# NUC029AN_v1 register map
File version: 1.0
Registers are 32-bit, read-write, reset 0x0 unless marked. A register's access mark holds for its fields unless they carry their own. Offsets are from the block's base; [hi:lo] are bit positions; {n}, {i} and the like mark numbered series; 'fields as' and 'values as' point back to an identical list.

## ADC — ADC Register Map
Base 0x400E0000
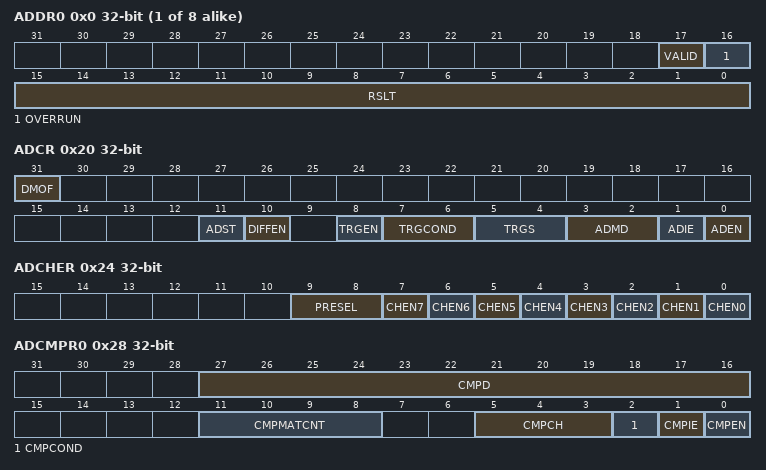
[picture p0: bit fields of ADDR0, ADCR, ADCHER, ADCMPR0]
{0x0+4i} ADDR{i} ro (i=0..7) — ADC Data Register {i}
  [17] VALID — Valid Flag. This bit is set to 1 when corresponding channel analog input conversion is completed and cleared by hardware after ADDR register is read. This is a read only bit
    0=Data in RSLT bits is not valid; 1=Data in RSLT bits is valid
  [16] OVERRUN — Over Run Flag (Read Only). If converted data in RSLT has not been read before new conversion result is loaded to this register, OVERRUN is set to 1. It is cleared by hardware after ADDR register is read.
    0=Data in RSLT is recent conversion result; 1=Data in RSLT is overwrite
  [15:0] RSLT — A/D Conversion Result. This field contains conversion result of ADC.
0x20 ADCR — ADC Control Register
  [31] DMOF — A/D differential input Mode Output Format
    0=A/D Conversion result will be filled in RSLT at ADDRx registers with unsigned format; 1=A/D Conversion result will be filled in RSLT at ADDRx registers with 2'complement format
  [11] ADST — A/D Conversion Start. ADST bit can be set to 1 from two sources: software and external pin STADC. ADST will be cleared to 0 by hardware automatically at the ends of single mode and single-cycle scan mode. In continuous scan and burst modes, A/D conversion is continuously performed until software write 0 to this bit or chip reset.
    0=Conversion stopped and A/D converter enter idle state; 1=Conversion start
  [10] DIFFEN — Differential Input Mode Enable
    0=single-end analog input mode; 1=differential analog input mode
  [8] TRGEN — External Trigger Enable. Enable or disable triggering of A/D conversion by external STADC pin or PWM trigger. ADC external trigger function is only supported in single-cycle scan mode.
    0=Disable; 1=Enable
  [7:6] TRGCOND — External Trigger Condition. These two bits decide external pin STADC trigger event is level or edge. The signal must be kept at stable state at least 8 PCLKs for level trigger and 4 PCLKs at high and low state for edge trigger.
    0=Low level; 1=High level; 2=Falling edge; 3=Rising edge
  [5:4] TRGS — Hardware Trigger Source. Software should disable TRGEN and ADST before change TRGS. In hardware trigger mode, the ADST bit is set by the external trigger from STADC.
    0=A/D conversion is started by external STADC pin; 3=A/D conversion is started by PWM trigger
  [3:2] ADMD — A/D Converter Operation Mode. When changing the operation mode, software should disable ADST bit firstly. Note: In Burst Mode, the A/D result data always at Data Register 0.
    0=Single conversion; 1=Burst conversion; 2=Single-cycle scan; 3=Continuous scan
  [1] ADIE — A/D Interrupt Enable. A/D conversion end interrupt request is generated if ADIE bit is set to 1.
    0=Disable A/D interrupt function; 1=Enable A/D interrupt function
  [0] ADEN — A/D Converter Enable. Before starting A/D conversion function, this bit should be set to 1. Clear it to 0 to disable A/D converter analog circuit power consumption.
    0=Disable; 1=Enable
0x24 ADCHER — ADC Channel Enable Register
  [9:8] PRESEL — Analog Input Channel 7 select. Note: When software select the band-gap voltage as the analog input source of ADC channel 7, ADC clock rate needs to be limited to lower than 300 KHz.
    0=External Analog Input; 1=Internal Bandgap voltage; 2=Internal temperature sensor
  [n] CHEN{n} (n=0..7) — Analog Input Channel {n} Enable
    0=Disable; 1=Enable
0x28 ADCMPR0 — ADC Compare Register 0
  [27:16] CMPD — Comparison Data. The 12 bits data is used to compare with conversion result of specified channel. When DMOF bit is set to 0, ADC comparator compares CMPD with conversion result with unsigned format. CMPD should be filled in unsigned format. When DMOF bit is set to 1, ADC comparator compares CMPD with conversion result with 2'complement format. CMPD should be filled in 2'complement format.
  [11:8] CMPMATCNT — Compare Match Count. When the specified A/D channel analog conversion result matches the compare condition defined by CMPCOND[2], the internal match counter will increase 1. When the internal counter reaches the value to (CMPMATCNT +1), the CMPFx bit will be set.
  [5:3] CMPCH — Compare Channel Selection
    {v}=Channel {v} conversion result is selected to be compared (v=0..7)
  [2] CMPCOND — Compare Condition. Note: When the internal counter reaches the value to (CMPMATCNT +1), the CMPFx bit will be set.
    0=Set the compare condition as that when a 12-bit A/D conversion result is less than the 12-bit CMPD (ADCMPRx[27:16]), the internal match counter will increase one; 1=Set the compare condition as that when a 12-bit A/D conversion result is greater or equal to the 12-bit CMPD (ADCMPRx[27:16]), the internal match counter will increase one
  [1] CMPIE — Compare Interrupt Enable. If the compare function is enabled and the compare condition matches the setting of CMPCOND and CMPMATCNT, CMPFx bit will be asserted, in the meanwhile, if CMPIE is set to 1, a compare interrupt request is generated.
    0=Disable compare function interrupt; 1=Enable compare function interrupt
  [0] CMPEN — Compare Enable. Set this bit to 1 to enable ADC controller to compare CMPD[11:0] with specified channel conversion result when converted data is loaded into ADDR register.
    0=Disable compare function; 1=Enable compare function
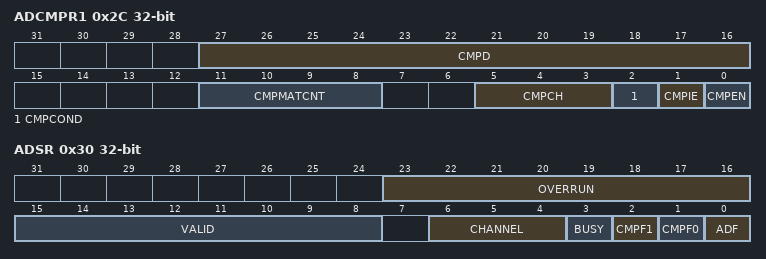
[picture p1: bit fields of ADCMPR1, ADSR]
0x2C ADCMPR1 — ADC Compare Register 1
  fields as ADCMPR0
0x30 ADSR — ADC Status Register
  [23:16] OVERRUN ro — Over Run flag (Read Only). It is a mirror to OVERRUN bit in ADDRx. When ADC in Burst Mode, and the FIFO is overrun, OVERRUN[7:0] will all set to 1.
  [15:8] VALID ro — Data Valid flag (Read Only). It is a mirror of VALID bit in ADDRx. When ADC in Burst Mode, and the FIFO is valid, VALID[7:0] will all set to 1.
  [6:4] CHANNEL — Current Conversion Channel. It is read only.
  [3] BUSY — BUSY/IDLE. This bit is mirror of as ADST bit in ADCR. It is read only.
    0=A/D converter is in idle state; 1=A/D converter is busy at conversion
  [2] CMPF1 — Compare Flag. When the selected channel A/D conversion result meets setting condition in ADCMPR1 then this bit is set to 1. And it is cleared by writing 1 to self.
    0=Conversion result in ADDR does not meet ADCMPR1 setting; 1=Conversion result in ADDR meets ADCMPR1 setting
  [1] CMPF0 — Compare Flag. When the selected channel A/D conversion result meets setting condition in ADCMPR0 then this bit is set to 1. And it is cleared by writing 1 to self.
    0=Conversion result in ADDR does not meet ADCMPR0 setting; 1=Conversion result in ADDR meets ADCMPR0setting
  [0] ADF — A/D Conversion End Flag. A status flag that indicates the end of A/D conversion. ADF is set to 1 at these three conditions: When A/D conversion ends in single mode. When A/D conversion ends on all specified channels in scan mode. When more than 4 samples in FIFO in Burst mode. This flag can be cleared by writing 1 to self.
0x44 ADTDCR — ADC Trigger Delay Control Register
  [7:0] PTDT — PWM Trigger Delay Time. Set this field will delay ADC start conversion time after PWM trigger is coming. PWM trigger delay time is (4 * PTDT) * system clock
